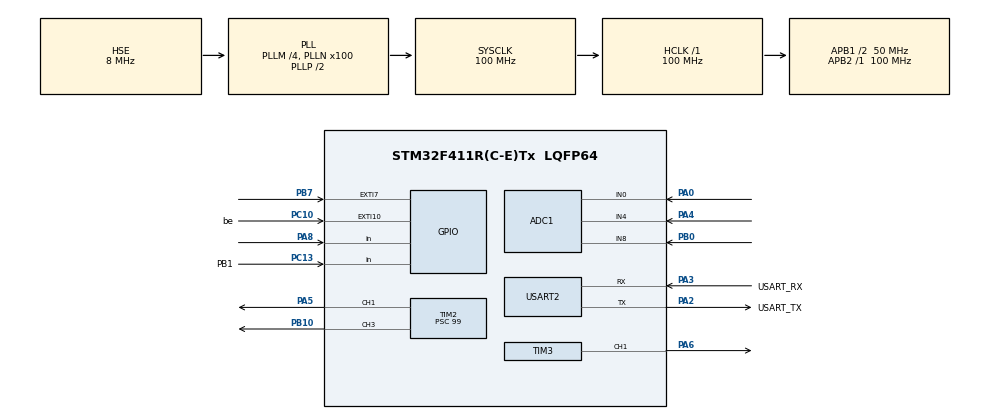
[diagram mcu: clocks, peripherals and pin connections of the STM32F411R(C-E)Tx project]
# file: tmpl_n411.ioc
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ADC1.Channel-0\#ChannelRegularConversion=ADC_CHANNEL_4
ADC1.NbrOfConversionFlag=1
ADC1.Rank-0\#ChannelRegularConversion=1
ADC1.SamplingTime-0\#ChannelRegularConversion=ADC_SAMPLETIME_3CYCLES
ADC1.master=1
Mcu.Family=STM32F4
Mcu.Name=STM32F411R(C-E)Tx
Mcu.Package=LQFP64
NVIC.EXTI15_10_IRQn=true\:0\:0\:false\:false\:true\:true\:true\:true
NVIC.EXTI9_5_IRQn=true\:0\:0\:false\:false\:true\:true\:true\:true
NVIC.PriorityGroup=NVIC_PRIORITYGROUP_0
NVIC.TIM5_IRQn=true\:0\:0\:false\:false\:true\:true\:true\:true
PA0-WKUP.Signal=ADCx_IN0
PA13.GPIO_Label=TMS
PA13.Mode=Serial_Wire
PA13.Signal=SYS_JTMS-SWDIO
PA14.GPIO_Label=TCK
PA14.Mode=Serial_Wire
PA14.Signal=SYS_JTCK-SWCLK
PA2.GPIO_Label=USART_TX
PA2.Mode=Asynchronous
PA2.Signal=USART2_TX
PA3.GPIO_Label=USART_RX
PA3.Mode=Asynchronous
PA3.Signal=USART2_RX
PA4.Signal=ADCx_IN4
PA5.Signal=S_TIM2_CH1_ETR
PA6.Signal=S_TIM3_CH1
PA8.Signal=GPIO_Input
PB0.Signal=ADCx_IN8
PB10.Signal=S_TIM2_CH3
PB3.GPIO_Label=SWO
PB3.Signal=SYS_JTDO-SWO
PB7.GPIO_ModeDefaultEXTI=GPIO_MODE_IT_FALLING
PB7.GPIO_PuPd=GPIO_PULLUP
PB7.Signal=GPXTI7
PC10.GPIO_Label=be
PC10.GPIO_PuPd=GPIO_PULLDOWN
PC10.Signal=GPXTI10
PC13-ANTI_TAMP.GPIO_Label=PB1
PC13-ANTI_TAMP.Signal=GPIO_Input
PC14-OSC32_IN.Mode=LSE-External-Oscillator
PC14-OSC32_IN.Signal=RCC_OSC32_IN
PC15-OSC32_OUT.Mode=LSE-External-Oscillator
PC15-OSC32_OUT.Signal=RCC_OSC32_OUT
PH0\ -\ OSC_IN.Mode=HSE-External-Clock-Source
PH0\ -\ OSC_IN.Signal=RCC_OSC_IN
PH1\ -\ OSC_OUT.Mode=HSE-External-Clock-Source
PH1\ -\ OSC_OUT.Signal=RCC_OSC_OUT
ProjectManager.HeapSize=0x200
ProjectManager.StackSize=0x400
ProjectManager.TargetToolchain=STM32CubeIDE
RCC.48MHZClocksFreq_Value=50000000
RCC.AHBFreq_Value=100000000
RCC.APB1CLKDivider=RCC_HCLK_DIV2
RCC.APB1Freq_Value=50000000
RCC.APB1TimFreq_Value=100000000
RCC.APB2Freq_Value=100000000
RCC.APB2TimFreq_Value=100000000
RCC.CortexFreq_Value=100000000
RCC.FLatency-AdvancedSettings=FLASH_LATENCY_3
RCC.HCLKFreq_Value=100000000
RCC.HSE_VALUE=8000000
RCC.HSI_VALUE=16000000
RCC.PLLM=4
RCC.PLLN=100
RCC.PLLSourceVirtual=RCC_PLLSOURCE_HSE
RCC.SYSCLKFreq_VALUE=100000000
RCC.SYSCLKSource=RCC_SYSCLKSOURCE_PLLCLK
RCC.VCOOutputFreq_Value=200000000
SH.ADCx_IN0.0=ADC1_IN0,IN0
SH.ADCx_IN4.0=ADC1_IN4,IN4
SH.ADCx_IN8.0=ADC1_IN8,IN8
SH.S_TIM2_CH1_ETR.0=TIM2_CH1,PWM Generation1 CH1
SH.S_TIM2_CH3.0=TIM2_CH3,PWM Generation3 CH3
SH.S_TIM3_CH1.0=TIM3_CH1,PWM Generation1 CH1
TIM2.Channel-PWM\ Generation1\ CH1=TIM_CHANNEL_1
TIM2.Channel-PWM\ Generation3\ CH3=TIM_CHANNEL_3
TIM2.Period=5000
TIM2.Prescaler=99
TIM3.Channel-PWM\ Generation1\ CH1=TIM_CHANNEL_1
TIM3.Period=5000
TIM3.Prescaler=99
TIM5.Period=999999
TIM5.Prescaler=99
USART2.VirtualMode=VM_ASYNC
VP_TIM2_VS_ClockSourceINT.Mode=Internal
VP_TIM3_VS_ClockSourceINT.Mode=Internal
VP_TIM5_VS_ClockSourceINT.Mode=Internal
board=NUCLEO-F411RE

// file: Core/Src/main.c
/* USER CODE BEGIN Header */
/**
  ******************************************************************************
  * @file           : main.c
  * @brief          : Main program body
  ******************************************************************************
  * @attention
  *
  * <h2><center>&copy; Copyright (c) 2021 STMicroelectronics.
  * All rights reserved.</center></h2>
  *
  * This software component is licensed by ST under BSD 3-Clause license,
  * the "License"; You may not use this file except in compliance with the
  * License. You may obtain a copy of the License at:
  *                        opensource.org/licenses/BSD-3-Clause
  *
  ******************************************************************************
  */
/* USER CODE END Header */
#include "main.h"
#include "adc.h"
#include "tim.h"
#include "usart.h"
#include "gpio.h"

void SystemClock_Config(void);

int main(void)
{

  /* MCU Configuration--------------------------------------------------------*/

  /* Reset of all peripherals, Initializes the Flash interface and the Systick. */
  HAL_Init();

  /* Configure the system clock */
  SystemClock_Config();

  /* Initialize all configured peripherals */
  MX_GPIO_Init();
  MX_USART2_UART_Init();
  MX_TIM2_Init();
  MX_TIM5_Init();
  MX_ADC1_Init();
  MX_TIM3_Init();
  /* USER CODE BEGIN 2 */
  HAL_TIM_PWM_Start(&htim2, TIM_CHANNEL_1);
  /* USER CODE END 2 */

  /* Infinite loop */
  /* USER CODE BEGIN WHILE */
  extern void app_init();
  app_init();
  while (1)
  {
    /* USER CODE END WHILE */

    /* USER CODE BEGIN 3 */
      extern void app_loop();
      app_loop();
  }
  /* USER CODE END 3 */
}

void SystemClock_Config(void)
{
  RCC_OscInitTypeDef RCC_OscInitStruct = {0};
  RCC_ClkInitTypeDef RCC_ClkInitStruct = {0};

  /** Configure the main internal regulator output voltage
  */
  __HAL_RCC_PWR_CLK_ENABLE();
  __HAL_PWR_VOLTAGESCALING_CONFIG(PWR_REGULATOR_VOLTAGE_SCALE1);

  /** Initializes the RCC Oscillators according to the specified parameters
  * in the RCC_OscInitTypeDef structure.
  */
  RCC_OscInitStruct.OscillatorType = RCC_OSCILLATORTYPE_HSE;
  RCC_OscInitStruct.HSEState = RCC_HSE_BYPASS;
  RCC_OscInitStruct.PLL.PLLState = RCC_PLL_ON;
  RCC_OscInitStruct.PLL.PLLSource = RCC_PLLSOURCE_HSE;
  RCC_OscInitStruct.PLL.PLLM = 4;
  RCC_OscInitStruct.PLL.PLLN = 100;
  RCC_OscInitStruct.PLL.PLLP = RCC_PLLP_DIV2;
  RCC_OscInitStruct.PLL.PLLQ = 4;
  if (HAL_RCC_OscConfig(&RCC_OscInitStruct) != HAL_OK)
  {
    Error_Handler();
  }

  /** Initializes the CPU, AHB and APB buses clocks
  */
  RCC_ClkInitStruct.ClockType = RCC_CLOCKTYPE_HCLK|RCC_CLOCKTYPE_SYSCLK
                              |RCC_CLOCKTYPE_PCLK1|RCC_CLOCKTYPE_PCLK2;
  RCC_ClkInitStruct.SYSCLKSource = RCC_SYSCLKSOURCE_PLLCLK;
  RCC_ClkInitStruct.AHBCLKDivider = RCC_SYSCLK_DIV1;
  RCC_ClkInitStruct.APB1CLKDivider = RCC_HCLK_DIV2;
  RCC_ClkInitStruct.APB2CLKDivider = RCC_HCLK_DIV1;

  if (HAL_RCC_ClockConfig(&RCC_ClkInitStruct, FLASH_LATENCY_3) != HAL_OK)
  {
    Error_Handler();
  }
}

void Error_Handler(void)
{
  __disable_irq();
  while (1)
  {
  }
}
